# K1921VG1T register map
Vendor: NIIET; Series: K1921VGx; File version: 2.8
CPU: other r0p1, little endian, MPU, FPU, 4 interrupt priority bits
Registers are 32-bit, read-write, reset 0x0 unless marked. A register's access mark holds for its fields unless they carry their own. Offsets are from the block's base; [hi:lo] are bit positions; lines under a group give offsets from that group; {n}, {i} and the like mark numbered series; 'fields as' and 'values as' point back to an identical list.

## SIU — System interconnect unit
Base 0x50003000
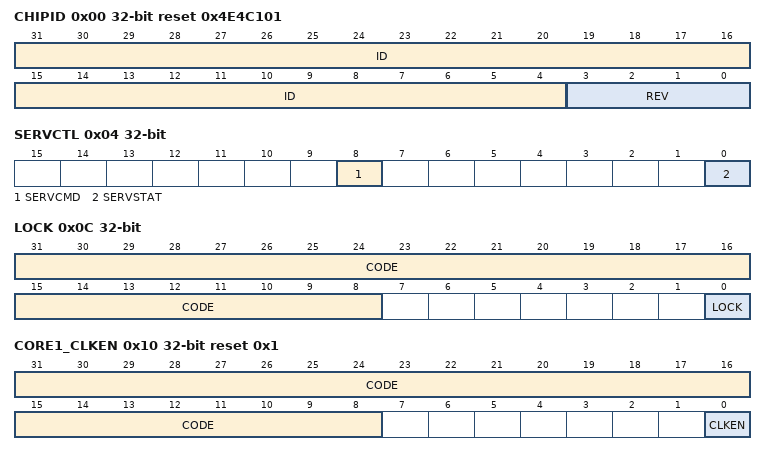
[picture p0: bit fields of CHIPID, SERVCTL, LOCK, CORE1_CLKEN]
0x00 CHIPID ro reset 0x4E4C101 — Chip identifier
  [31:4] ID — Model ID
  [3:0] REV — Revision number
0x04 SERVCTL — Service mode register
  [8] SERVCMD — Service mode erase comand/status
  [0] SERVSTAT ro — Service mode status
0x08 CPESTAT ro — CPE status register
  [0] CPE — Status of CPE PAD latched
0x0C LOCK — Lock configuration register
  [31:8] CODE wo — Write key 0xACCE55 to change LOCK bit value
  [0] LOCK — Write with specific code to lock / unlock SIU registers configuration
0x10 CORE1_CLKEN wo reset 0x1 — Core 1 clock enable register
  [31:8] CODE — Write key 0xACCE55 to change CLKEN bit value when in DUALCORE mode
  [0] CLKEN — Clock enable for Core 1
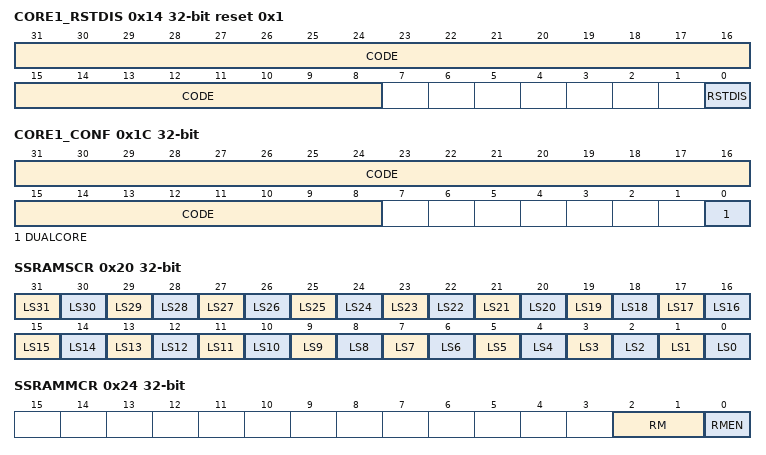
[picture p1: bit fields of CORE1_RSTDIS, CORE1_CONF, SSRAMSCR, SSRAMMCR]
0x14 CORE1_RSTDIS wo reset 0x1 — Core 1 reset disable register
  [31:8] CODE — Write key 0xACCE55 to change RSTDIS bit value when in DUALCORE mode
  [0] RSTDIS — Reset disable for Core 1
0x18 CORE1_RVECT — Core 1 reset vector register
  [31:0] RVECT — Reset vector (affected only in DUALCORE mode)
0x1C CORE1_CONF — Core 1 configuration register
  [31:8] CODE wo — Write key 0xACCE55 to change LOCK bit value
  [0] DUALCORE — If set, second core work independent from first core
    0=LOCKSTEP (Second core work in lockstep mode); 1=DUALCORE (Second core work independently)
0x20 SSRAMSCR — System SRAM sleep control register
  [31] LS31 — Light Sleep RAM part 31 (992k..1024k)
  [30] LS30 — Light Sleep RAM part 30 (960k..992k)
  [29] LS29 — Light Sleep RAM part 29 (928k..960k)
  [28] LS28 — Light Sleep RAM part 28 (896k..928k)
  [27] LS27 — Light Sleep RAM part 27 (864k..896k)
  [26] LS26 — Light Sleep RAM part 26 (832k..864k)
  [25] LS25 — Light Sleep RAM part 25 (800k..832k)
  [24] LS24 — Light Sleep RAM part 24 (768k..800k)
  [23] LS23 — Light Sleep RAM part 23 (736k..768k)
  [22] LS22 — Light Sleep RAM part 22 (704k..736k)
  [21] LS21 — Light Sleep RAM part 21 (672k..704k)
  [20] LS20 — Light Sleep RAM part 20 (640k..672k)
  [19] LS19 — Light Sleep RAM part 19 (608k..640k)
  [18] LS18 — Light Sleep RAM part 18 (576k..608k)
  [17] LS17 — Light Sleep RAM part 17 (544k..576k)
  [16] LS16 — Light Sleep RAM part 16 (512k..544k)
  [15] LS15 — Light Sleep RAM part 15 (480k..512k)
  [14] LS14 — Light Sleep RAM part 14 (448k..480k)
  [13] LS13 — Light Sleep RAM part 13 (416k..448k)
  [12] LS12 — Light Sleep RAM part 12 (384k..416k)
  [11] LS11 — Light Sleep RAM part 11 (352k..384k)
  [10] LS10 — Light Sleep RAM part 10 (320k..352k)
  [9] LS9 — Light Sleep RAM part 9 (288k..320k)
  [8] LS8 — Light Sleep RAM part 8 (256k..288k)
  [7] LS7 — Light Sleep RAM part 7 (224k..256k)
  [6] LS6 — Light Sleep RAM part 6 (192k..224k)
  [5] LS5 — Light Sleep RAM part 5 (160k..192k)
  [4] LS4 — Light Sleep RAM part 4 (128k..160k)
  [3] LS3 — Light Sleep RAM part 3 (96k..128k)
  [2] LS2 — Light Sleep RAM part 2 (64k..96k)
  [1] LS1 — Light Sleep RAM part 1 (32k..64k)
  [0] LS0 — Light Sleep RAM part 0 (0..32k)
0x24 SSRAMMCR — System SRAM margin control register
  [2:1] RM — Read-Write Margin value
  [0] RMEN — Enable to use Read-Write Margin
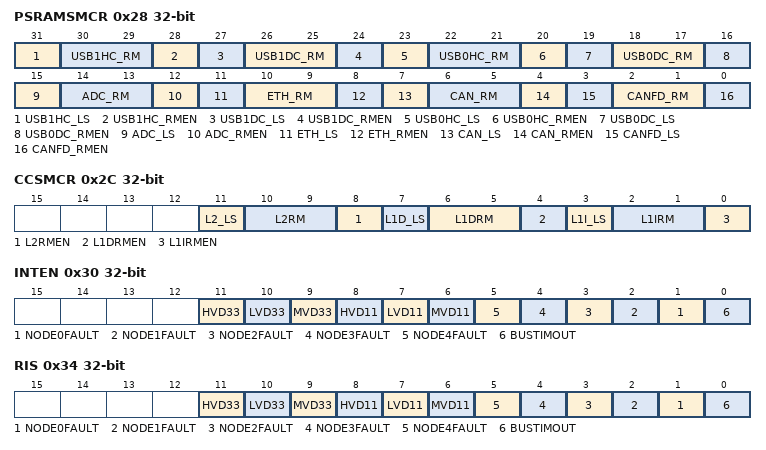
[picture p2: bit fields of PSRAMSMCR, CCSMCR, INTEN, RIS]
0x28 PSRAMSMCR — Periperals SRAM sleep and margin control register
  [31] USB1HC_LS — Light Sleep USB1 Host RAM (currently unsupported)
  [30:29] USB1HC_RM — Read-Write USB1 Host RAM Margin value (currently unsupported)
  [28] USB1HC_RMEN — Enable to use Read-Write Margin on USB1 Host RAM (currently unsupported)
  [27] USB1DC_LS — Light Sleep USB1 Device RAM (currently unsupported)
  [26:25] USB1DC_RM — Read-Write USB1 Device RAM Margin value (currently unsupported)
  [24] USB1DC_RMEN — Enable to use Read-Write Margin on USB1 Device RAM (currently unsupported)
  [23] USB0HC_LS — Light Sleep USB0 Host RAM
  [22:21] USB0HC_RM — Read-Write USB0 Host RAM Margin value
  [20] USB0HC_RMEN — Enable to use Read-Write Margin on USB0 Host RAM
  [19] USB0DC_LS — Light Sleep USB0 Device RAM
  [18:17] USB0DC_RM — Read-Write USB0 Device RAM Margin value
  [16] USB0DC_RMEN — Enable to use Read-Write Margin on USB0 Device RAM
  [15] ADC_LS — Light Sleep ADC RAM
  [14:13] ADC_RM — Read-Write ADC RAM Margin value
  [12] ADC_RMEN — Enable to use Read-Write Margin on ADC RAM
  [11] ETH_LS — Light Sleep Ethernet RAM
  [10:9] ETH_RM — Read-Write Ethernet RAM Margin value
  [8] ETH_RMEN — Enable to use Read-Write Margin on Ethernet RAM
  [7] CAN_LS — Light Sleep CAN RAM
  [6:5] CAN_RM — Read-Write CAN RAM Margin value
  [4] CAN_RMEN — Enable to use Read-Write Margin on CAN RAM
  [3] CANFD_LS — Light Sleep CANFD RAM
  [2:1] CANFD_RM — Read-Write CANFD RAM Margin value
  [0] CANFD_RMEN — Enable to use Read-Write Margin on CANFD RAM
0x2C CCSMCR — Core caches sleep and margin control register
  [11] L2_LS — Light Sleep Control for L2 Cache
  [10:9] L2RM — Read-Write Margin value for L2 Cache
  [8] L2RMEN — Enable to use Read-Write Margin for L2 Cache
  [7] L1D_LS — Light Sleep Control for L1D Cache
  [6:5] L1DRM — Read-Write Margin value for L1D Cache
  [4] L1DRMEN — Enable to use Read-Write Margin for L1D Cache
  [3] L1I_LS — Light Sleep Control for L1I Cache
  [2:1] L1IRM — Read-Write Margin value for L1I Cache
  [0] L1IRMEN — Enable to use Read-Write Margin for L1I Cache
0x30 INTEN — Interrupt enable register
  [11] HVD33 — Enable High Voltage Detect on AVDD supply line interrupt
  [10] LVD33 — Enable Low Voltage Detect on AVDD supply line interrupt
  [9] MVD33 — Enable Minimal Voltage Detect on AVDD supply line interrupt
  [8] HVD11 — Enable High Voltage Detect on DVDD supply line interrupt
  [7] LVD11 — Enable Low Voltage Detect on DVDD supply line interrupt
  [6] MVD11 — Enable Minimal Voltage Detect on DVDD supply line interrupt
  [n+1] NODE{n}FAULT (n=0..4) — Enable node {n} fault interrupt
  [0] BUSTIMOUT — Enable bus timeout interrupt
0x34 RIS ro — Raw interrupt status register
  [11] HVD33 — High Voltage Detect on AVDD supply line status
  [10] LVD33 — Low Voltage Detect on AVDD supply line status
  [9] MVD33 — Minimal Voltage Detect on AVDD supply line status
  [8] HVD11 — High Voltage Detect on DVDD supply line status
  [7] LVD11 — Low Voltage Detect on DVDD supply line status
  [6] MVD11 — Minimal Voltage Detect on DVDD supply line status
  [n+1] NODE{n}FAULT (n=0..4) — Node {n} fault status
  [0] BUSTIMOUT — Bus timeout interrupt status
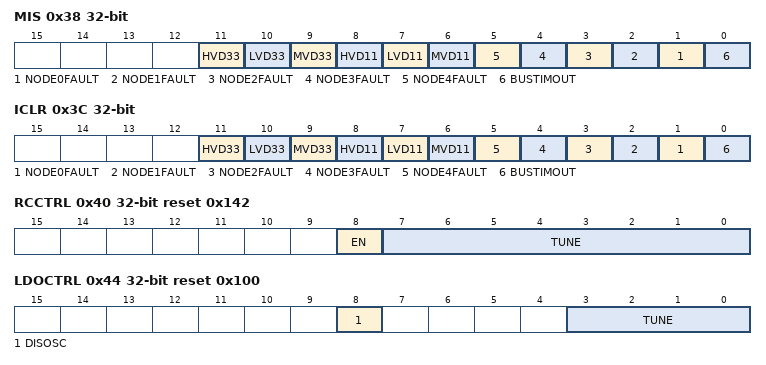
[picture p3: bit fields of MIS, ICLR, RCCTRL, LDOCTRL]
0x38 MIS ro — Masked interrupt status register
  [11] HVD33 — High Voltage Detect on AVDD supply line masked status
  [10] LVD33 — Low Voltage Detect on AVDD supply line masked status
  [9] MVD33 — Minimal Voltage Detect on AVDD supply line masked status
  [8] HVD11 — High Voltage Detect on DVDD supply line masked status
  [7] LVD11 — Low Voltage Detect on DVDD supply line masked status
  [6] MVD11 — Minimal Voltage Detect on DVDD supply line masked status
  [n+1] NODE{n}FAULT (n=0..4) — Node {n} fault masked status
  [0] BUSTIMOUT — Masked status of bus timeout interrupt
0x3C ICLR wo — Interrupt clear register
  [11] HVD33 — Clear High Voltage Detect on AVDD supply line interrupt
  [10] LVD33 — Clear Low Voltage Detect on AVDD supply line interrupt
  [9] MVD33 — Clear Minimal Voltage Detect on AVDD supply line interrupt
  [8] HVD11 — Clear High Voltage Detect on DVDD supply line interrupt
  [7] LVD11 — Clear Low Voltage Detect on DVDD supply line interrupt
  [6] MVD11 — Clear Minimal Voltage Detect on DVDD supply line interrupt
  [n+1] NODE{n}FAULT (n=0..4) — Clear node {n} fault interrupt
  [0] BUSTIMOUT — Clear bus timeout interrupt
0x40 RCCTRL reset 0x142 — RC generator control register
  [8] EN — Internal oscillator enable
  [7:0] TUNE — Tune RC generator period
0x44 LDOCTRL reset 0x100 — LDO control register
  [8] DISOSC — Disable 100kHz oscillator
    0=ENABLEOSC (Enable 100kHz oscillator); 1=DISABLEOSC (Disable 100kHz oscillator)
  [3:0] TUNE — Tune LDO output voltage
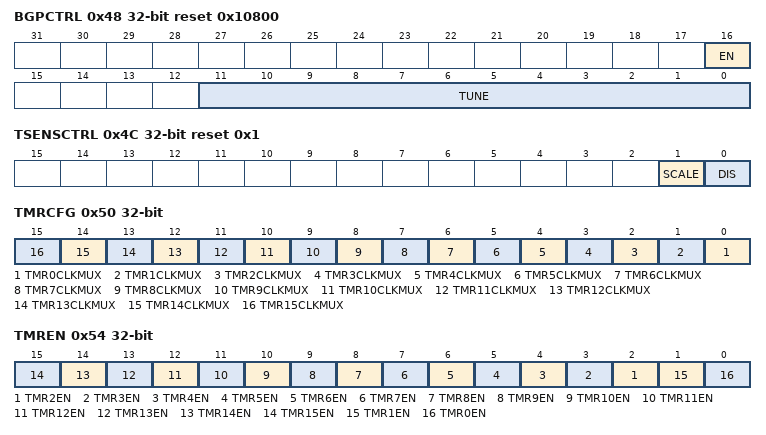
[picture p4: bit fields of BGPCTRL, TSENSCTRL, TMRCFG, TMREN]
0x48 BGPCTRL reset 0x10800 — Bandgap control register
  [16] EN — Enable bandgap
  [11:0] TUNE — Tune bandgap voltage
0x4C TSENSCTRL reset 0x1 — Tempreture sensor control register
  [1] SCALE — Scale out control
  [0] DIS — Disable tsensor
0x50 TMRCFG — Timers external clock config
  [all] fields
    0=EXTPIN (external controler pin); 1=PRETIMER (previous timer PWM-output)
  [n] TMR{n}CLKMUX (n=0..15) — Select ecternal clock source
0x54 TMREN — Timers counting enable register
  [n] TMR{n}EN (n=2..15) — Enable count for timer {n}
  [1] TMR1EN — Enable count for TMR 1
  [0] TMR0EN — Enable count for TMR 0
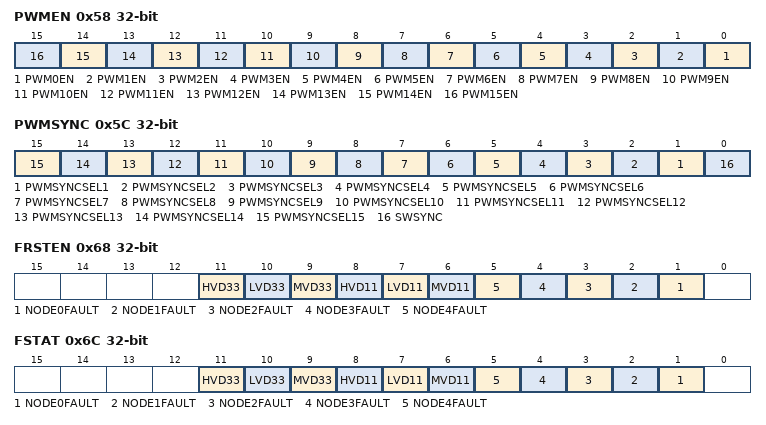
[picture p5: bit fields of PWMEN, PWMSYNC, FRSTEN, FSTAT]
0x58 PWMEN — PWM counting enable register
  [n] PWM{n}EN (n=0..15) — Enable count for PWM {n}
0x5C PWMSYNC — Sync PWM register
  [n] PWMSYNCSEL{n} (n=1..15) — PWM sync scheme control
  [0] SWSYNC — SYNCI pulse software emulation on PWM0
0x60 EMMUXCTRL — Extrernal memory multiplexor control register
  [0] SDRAMEN — Connect outputs of SDRAM IP to external memory mapped GPIO pins
    0=EMC (EMC connected to external memory mapped GPIO pins); 1=SDRAM (SDRAM connected to external memory mapped GPIO pins)
0x64 TIMEOUT reset 0xFFFF
  [15:0] VALUE — Timeout value
0x68 FRSTEN — Fault reset enable register
  [11] HVD33 — Enable High Voltage Detect on AVDD supply line reset
  [10] LVD33 — Enable Low Voltage Detect on AVDD supply line reset
  [9] MVD33 — Enable Minimal Voltage Detect on AVDD supply line reset
  [8] HVD11 — Enable High Voltage Detect on DVDD supply line reset
  [7] LVD11 — Enable Low Voltage Detect on DVDD supply line reset
  [6] MVD11 — Enable Minimal Voltage Detect on DVDD supply line reset
  [n+1] NODE{n}FAULT (n=0..4) — Enable node {n} fault reset
0x6C FSTAT — Fault status regsiter
  [11] HVD33 — Fault reset due High Voltage Detect on AVDD supply line
  [10] LVD33 — Fault reset due Low Voltage Detect on AVDD supply line
  [9] MVD33 — Fault reset due Minimal Voltage Detect on AVDD supply line
  [8] HVD11 — Fault reset due High Voltage Detect on DVDD supply line
  [7] LVD11 — Fault reset due Low Voltage Detect on DVDD supply line
  [6] MVD11 — Fault reset due Minimal Voltage Detect on DVDD supply line
  [n+1] NODE{n}FAULT (n=0..4) — Fault reset due node {n} fault
{0x70+4i} TMRMUX[{i}] (i=0..15) group
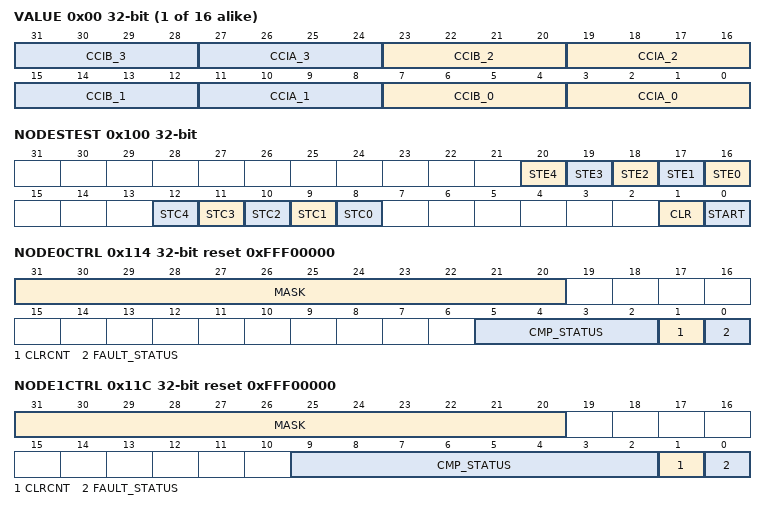
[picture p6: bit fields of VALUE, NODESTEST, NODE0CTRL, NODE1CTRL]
  0x00 VALUE — TMRxx ccix input select (0-3 array consist of full 32 bit register, 4-16 only CCI*_0)
    [all] fields
      {v}=TMRIO{v} (External pin) (v=0..3); 4=GPIOAB (GPIOA or GPIOB adc soc impulse); 5=GPIOCD (GPIOC or GPIOD adc soc impulse); 6=GPIOEF (GPIOE or GPIOF adc soc impulse); 7=GPIOG (GPIOG adc soc impulse); 8=PWM0_3A (PWM0-3 adc soc channel A impulse); 9=PWM4_7A (PWM4-7 adc soc channel A impulse); 10=PWM8_11A (PWM8-11 adc soc channel A impulse); 11=PWM12_15A (PWM12-15 adc soc channel A impulse); 12=PWM0_3B (PWM0-3 adc soc channel B impulse); 13=PWM4_7B (PWM4-7 adc soc channel B impulse); 14=PWM8_11B (PWM8-11 adc soc channel B impulse); 15=PWM12_15B (PWM12-15 adc soc channel B impulse)
    [8n+7:8n+4] CCIB_{n} (n=0..3) — Select signal for TMRxx CCIB {n} input
    [8n+3:8n] CCIA_{n} (n=0..3) — Select signal for TMRxx CCIA {n} input
0x100 NODESTEST — Nodes selftest start and status register
  [n+16] STE{n} ro (n=0..4) — Self test for node {n} ends with errors
  [n+8] STC{n} ro (n=0..4) — Self test for node {n} complete
  [1] CLR wo — Clear status bits
  [0] START wo — Start nodes selftest
{0x110+8i} NODE{i}ECNT ro (i=0..4) — Node {i} error counter register
  [11:0] VALUE — Number of errors in current node
0x114 NODE0CTRL reset 0xFFF00000 — Node 0 control register
  [31:20] MASK — Node maximum errors selector
  [5:2] CMP_STATUS — Node comparator status
  [1] CLRCNT wo — Clear error counter
  [0] FAULT_STATUS — Node fault status
0x11C NODE1CTRL reset 0xFFF00000 — Node 1 control register
  [31:20] MASK — Node maximum errors selector
  [9:2] CMP_STATUS — Node comparator status
  [1] CLRCNT wo — Clear error counter
  [0] FAULT_STATUS — Node fault status
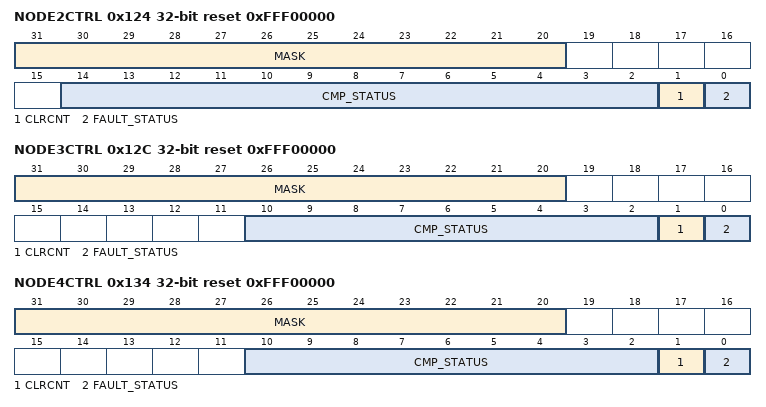
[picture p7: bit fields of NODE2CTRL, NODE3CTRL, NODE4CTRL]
0x124 NODE2CTRL reset 0xFFF00000 — Node 2 control register
  [31:20] MASK — Node maximum errors selector
  [14:2] CMP_STATUS — Node comparator status
  [1] CLRCNT wo — Clear error counter
  [0] FAULT_STATUS — Node fault status
0x12C NODE3CTRL reset 0xFFF00000 — Node 3 control register
  [31:20] MASK — Node maximum errors selector
  [10:2] CMP_STATUS — Node comparator status
  [1] CLRCNT wo — Clear error counter
  [0] FAULT_STATUS — Node fault status
0x134 NODE4CTRL reset 0xFFF00000 — Node 4 control register
  fields as NODE3CTRL
